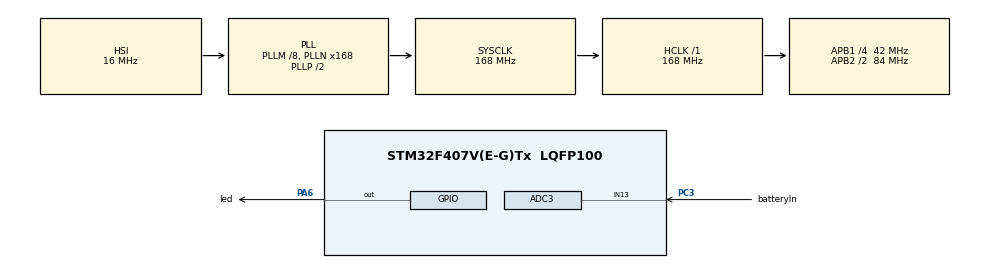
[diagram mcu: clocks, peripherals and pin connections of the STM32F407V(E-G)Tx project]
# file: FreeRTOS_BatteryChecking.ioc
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ADC3.Channel-0\#ChannelRegularConversion=ADC_CHANNEL_13
ADC3.NbrOfConversionFlag=1
ADC3.Rank-0\#ChannelRegularConversion=1
ADC3.SamplingTime-0\#ChannelRegularConversion=ADC_SAMPLETIME_3CYCLES
FREERTOS.BinarySemaphores01=lowBattSem,Dynamic,NULL
FREERTOS.Tasks01=mainTask,0,128,StartMainTask,Default,NULL,Dynamic,NULL,NULL;checkBattery,-1,128,StartCheckBattery,Default,NULL,Dynamic,NULL,NULL
Mcu.Family=STM32F4
Mcu.Name=STM32F407V(E-G)Tx
Mcu.Package=LQFP100
NVIC.PriorityGroup=NVIC_PRIORITYGROUP_4
NVIC.TIM7_IRQn=true\:0\:0\:false\:false\:true\:false\:false\:true
NVIC.TimeBase=TIM7_IRQn
NVIC.TimeBaseIP=TIM7
PA13.Mode=Serial_Wire
PA13.Signal=SYS_JTMS-SWDIO
PA14.Mode=Serial_Wire
PA14.Signal=SYS_JTCK-SWCLK
PA6.GPIO_Label=led
PA6.GPIO_PuPd=GPIO_PULLDOWN
PA6.Signal=GPIO_Output
PC3.GPIO_Label=batteryIn
PC3.Signal=ADCx_IN13
PH0-OSC_IN.Mode=HSE-External-Oscillator
PH0-OSC_IN.Signal=RCC_OSC_IN
PH1-OSC_OUT.Mode=HSE-External-Oscillator
PH1-OSC_OUT.Signal=RCC_OSC_OUT
ProjectManager.HeapSize=0x200
ProjectManager.StackSize=0x400
ProjectManager.TargetToolchain=STM32CubeIDE
RCC.48MHZClocksFreq_Value=84000000
RCC.AHBFreq_Value=168000000
RCC.APB1CLKDivider=RCC_HCLK_DIV4
RCC.APB1Freq_Value=42000000
RCC.APB1TimFreq_Value=84000000
RCC.APB2CLKDivider=RCC_HCLK_DIV2
RCC.APB2Freq_Value=84000000
RCC.APB2TimFreq_Value=168000000
RCC.CortexFreq_Value=168000000
RCC.HCLKFreq_Value=168000000
RCC.HSE_VALUE=8000000
RCC.HSI_VALUE=16000000
RCC.LSE_VALUE=32768
RCC.PLLM=8
RCC.PLLN=168
RCC.SYSCLKFreq_VALUE=168000000
RCC.SYSCLKSource=RCC_SYSCLKSOURCE_PLLCLK
RCC.VCOOutputFreq_Value=336000000
SH.ADCx_IN13.0=ADC3_IN13,IN13
VP_FREERTOS_VS_CMSIS_V1.Mode=CMSIS_V1
VP_SYS_VS_tim7.Mode=TIM7
board=custom

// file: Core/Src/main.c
/* USER CODE BEGIN Header */
/**
  ******************************************************************************
  * @file           : main.c
  * @brief          : Main program body
  ******************************************************************************
  * @attention
  *
  * <h2><center>&copy; Copyright (c) 2020 STMicroelectronics.
  * All rights reserved.</center></h2>
  *
  * This software component is licensed by ST under BSD 3-Clause license,
  * the "License"; You may not use this file except in compliance with the
  * License. You may obtain a copy of the License at:
  *                        opensource.org/licenses/BSD-3-Clause
  *
  ******************************************************************************
  */
/* USER CODE END Header */

#include "main.h"
#include "cmsis_os.h"

/* USER CODE BEGIN Includes */
#include "stdbool.h"

static const uint32_t batteryCheckingPeriod = 3000;
static const uint32_t lowBatteryVoltage = 1200;
/* USER CODE END Includes */

ADC_HandleTypeDef hadc3;

osThreadId mainTaskHandle;
osThreadId checkBatteryHandle;
osSemaphoreId lowBattSemHandle;
/* USER CODE BEGIN PV */
volatile uint32_t battVoltage = 0;
/* USER CODE END PV */

void SystemClock_Config(void);
static void MX_GPIO_Init(void);
static void MX_ADC3_Init(void);
void StartMainTask(void const * argument);
void StartCheckBattery(void const * argument);

int main(void)
{

  /* MCU Configuration--------------------------------------------------------*/

  /* Reset of all peripherals, Initializes the Flash interface and the Systick. */
  HAL_Init();

  /* Configure the system clock */
  SystemClock_Config();

  /* Initialize all configured peripherals */
  MX_GPIO_Init();
  MX_ADC3_Init();

  /* Create the semaphores(s) */
  /* definition and creation of lowBattSem */
  osSemaphoreDef(lowBattSem);
  lowBattSemHandle = osSemaphoreCreate(osSemaphore(lowBattSem), 1);

  /* Create the thread(s) */
  /* definition and creation of mainTask */
  osThreadDef(mainTask, StartMainTask, osPriorityNormal, 0, 128);
  mainTaskHandle = osThreadCreate(osThread(mainTask), NULL);

  /* definition and creation of checkBattery */
  osThreadDef(checkBattery, StartCheckBattery, osPriorityBelowNormal, 0, 128);
  checkBatteryHandle = osThreadCreate(osThread(checkBattery), NULL);

  /* Start scheduler */
  osKernelStart();

  /* We should never get here as control is now taken by the scheduler */
  /* Infinite loop */
  while (1)
  {

  }
}

void SystemClock_Config(void)
{
  RCC_OscInitTypeDef RCC_OscInitStruct = {0};
  RCC_ClkInitTypeDef RCC_ClkInitStruct = {0};

  /** Configure the main internal regulator output voltage
  */
  __HAL_RCC_PWR_CLK_ENABLE();
  __HAL_PWR_VOLTAGESCALING_CONFIG(PWR_REGULATOR_VOLTAGE_SCALE1);
  /** Initializes the CPU, AHB and APB busses clocks
  */
  RCC_OscInitStruct.OscillatorType = RCC_OSCILLATORTYPE_HSI;
  RCC_OscInitStruct.HSIState = RCC_HSI_ON;
  RCC_OscInitStruct.HSICalibrationValue = RCC_HSICALIBRATION_DEFAULT;
  RCC_OscInitStruct.PLL.PLLState = RCC_PLL_ON;
  RCC_OscInitStruct.PLL.PLLSource = RCC_PLLSOURCE_HSI;
  RCC_OscInitStruct.PLL.PLLM = 8;
  RCC_OscInitStruct.PLL.PLLN = 168;
  RCC_OscInitStruct.PLL.PLLP = RCC_PLLP_DIV2;
  RCC_OscInitStruct.PLL.PLLQ = 4;
  if (HAL_RCC_OscConfig(&RCC_OscInitStruct) != HAL_OK)
  {
    Error_Handler();
  }
  /** Initializes the CPU, AHB and APB busses clocks
  */
  RCC_ClkInitStruct.ClockType = RCC_CLOCKTYPE_HCLK|RCC_CLOCKTYPE_SYSCLK
                              |RCC_CLOCKTYPE_PCLK1|RCC_CLOCKTYPE_PCLK2;
  RCC_ClkInitStruct.SYSCLKSource = RCC_SYSCLKSOURCE_PLLCLK;
  RCC_ClkInitStruct.AHBCLKDivider = RCC_SYSCLK_DIV1;
  RCC_ClkInitStruct.APB1CLKDivider = RCC_HCLK_DIV4;
  RCC_ClkInitStruct.APB2CLKDivider = RCC_HCLK_DIV2;

  if (HAL_RCC_ClockConfig(&RCC_ClkInitStruct, FLASH_LATENCY_5) != HAL_OK)
  {
    Error_Handler();
  }
}

static void MX_ADC3_Init(void)
{

  ADC_ChannelConfTypeDef sConfig = {0};

  /** Configure the global features of the ADC (Clock, Resolution, Data Alignment and number of conversion)
  */
  hadc3.Instance = ADC3;
  hadc3.Init.ClockPrescaler = ADC_CLOCK_SYNC_PCLK_DIV4;
  hadc3.Init.Resolution = ADC_RESOLUTION_12B;
  hadc3.Init.ScanConvMode = DISABLE;
  hadc3.Init.ContinuousConvMode = DISABLE;
  hadc3.Init.DiscontinuousConvMode = DISABLE;
  hadc3.Init.ExternalTrigConvEdge = ADC_EXTERNALTRIGCONVEDGE_NONE;
  hadc3.Init.ExternalTrigConv = ADC_SOFTWARE_START;
  hadc3.Init.DataAlign = ADC_DATAALIGN_RIGHT;
  hadc3.Init.NbrOfConversion = 1;
  hadc3.Init.DMAContinuousRequests = DISABLE;
  hadc3.Init.EOCSelection = ADC_EOC_SINGLE_CONV;
  if (HAL_ADC_Init(&hadc3) != HAL_OK)
  {
    Error_Handler();
  }
  /** Configure for the selected ADC regular channel its corresponding rank in the sequencer and its sample time.
  */
  sConfig.Channel = ADC_CHANNEL_13;
  sConfig.Rank = 1;
  sConfig.SamplingTime = ADC_SAMPLETIME_3CYCLES;
  if (HAL_ADC_ConfigChannel(&hadc3, &sConfig) != HAL_OK)
  {
    Error_Handler();
  }

}

static void MX_GPIO_Init(void)
{
  GPIO_InitTypeDef GPIO_InitStruct = {0};

  /* GPIO Ports Clock Enable */
  __HAL_RCC_GPIOH_CLK_ENABLE();
  __HAL_RCC_GPIOC_CLK_ENABLE();
  __HAL_RCC_GPIOA_CLK_ENABLE();

  /*Configure GPIO pin Output Level */
  HAL_GPIO_WritePin(led_GPIO_Port, led_Pin, GPIO_PIN_RESET);

  /*Configure GPIO pin : led_Pin */
  GPIO_InitStruct.Pin = led_Pin;
  GPIO_InitStruct.Mode = GPIO_MODE_OUTPUT_PP;
  GPIO_InitStruct.Pull = GPIO_PULLDOWN;
  GPIO_InitStruct.Speed = GPIO_SPEED_FREQ_LOW;
  HAL_GPIO_Init(led_GPIO_Port, &GPIO_InitStruct);

}

void StartMainTask(void const * argument)
{
  /* USER CODE BEGIN 5 */
  /* Infinite loop */
  for(;;)
  {
	  osSemaphoreWait(lowBattSemHandle, osWaitForever);
	  HAL_GPIO_TogglePin(led_GPIO_Port, led_Pin);
      osDelay(100);
      if(battVoltage > lowBatteryVoltage) osSemaphoreRelease(lowBattSemHandle);
  }
  /* USER CODE END 5 */
}

void StartCheckBattery(void const * argument)
{
  /* USER CODE BEGIN StartCheckBattery */
  /* Infinite loop */
  for(;;)
  {
	  HAL_ADC_Start(&hadc3);
	  battVoltage = HAL_ADC_GetValue(&hadc3);
	  if(battVoltage > lowBatteryVoltage) osSemaphoreRelease(lowBattSemHandle);
      osDelay((uint32_t)batteryCheckingPeriod);
  }
  /* USER CODE END StartCheckBattery */
}

 /**
  * @brief  Period elapsed callback in non blocking mode
  * @note   This function is called  when TIM7 interrupt took place, inside
  * HAL_TIM_IRQHandler(). It makes a direct call to HAL_IncTick() to increment
  * a global variable "uwTick" used as application time base.
  * @param  htim : TIM handle
  * @retval None
  */
void HAL_TIM_PeriodElapsedCallback(TIM_HandleTypeDef *htim)
{
  if (htim->Instance == TIM7) {
    HAL_IncTick();
  }
}

void Error_Handler(void)
{
}

/************************ (C) COPYRIGHT STMicroelectronics *****END OF FILE****/
